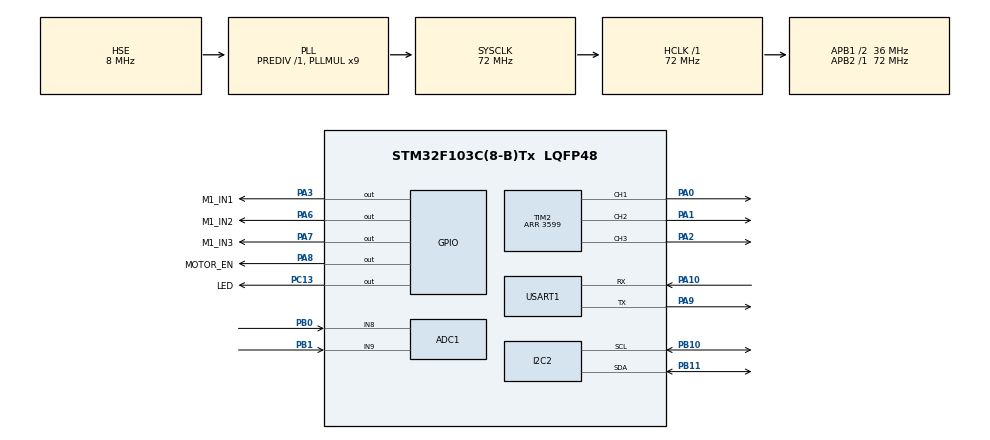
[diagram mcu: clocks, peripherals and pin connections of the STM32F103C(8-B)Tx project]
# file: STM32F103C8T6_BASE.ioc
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ADC1.Channel-0\#ChannelRegularConversion=ADC_CHANNEL_8
ADC1.Channel-1\#ChannelRegularConversion=ADC_CHANNEL_9
ADC1.NbrOfConversion=2
ADC1.NbrOfConversionFlag=1
ADC1.Rank-0\#ChannelRegularConversion=1
ADC1.Rank-1\#ChannelRegularConversion=2
ADC1.SamplingTime-0\#ChannelRegularConversion=ADC_SAMPLETIME_55CYCLES_5
ADC1.SamplingTime-1\#ChannelRegularConversion=ADC_SAMPLETIME_55CYCLES_5
ADC1.master=1
Mcu.Family=STM32F1
Mcu.Name=STM32F103C(8-B)Tx
Mcu.Package=LQFP48
NVIC.PriorityGroup=NVIC_PRIORITYGROUP_4
PA0-WKUP.Signal=S_TIM2_CH1_ETR
PA1.Signal=S_TIM2_CH2
PA10.Mode=Asynchronous
PA10.Signal=USART1_RX
PA13.Mode=Serial_Wire
PA13.Signal=SYS_JTMS-SWDIO
PA14.Mode=Serial_Wire
PA14.Signal=SYS_JTCK-SWCLK
PA2.Signal=S_TIM2_CH3
PA3.GPIO_Label=M1_IN1
PA3.Signal=GPIO_Output
PA6.GPIO_Label=M1_IN2
PA6.Signal=GPIO_Output
PA7.GPIO_Label=M1_IN3
PA7.Signal=GPIO_Output
PA8.GPIO_Label=MOTOR_EN
PA8.GPIO_PuPd=GPIO_NOPULL
PA8.Signal=GPIO_Output
PA9.Mode=Asynchronous
PA9.Signal=USART1_TX
PB0.Signal=ADCx_IN8
PB1.Signal=ADCx_IN9
PB10.Mode=I2C
PB10.Signal=I2C2_SCL
PB11.Mode=I2C
PB11.Signal=I2C2_SDA
PC13-TAMPER-RTC.GPIO_Label=LED
PC13-TAMPER-RTC.Signal=GPIO_Output
PC14-OSC32_IN.Mode=LSE-External-Oscillator
PC14-OSC32_IN.Signal=RCC_OSC32_IN
PC15-OSC32_OUT.Mode=LSE-External-Oscillator
PC15-OSC32_OUT.Signal=RCC_OSC32_OUT
PD0-OSC_IN.Mode=HSE-External-Oscillator
PD0-OSC_IN.Signal=RCC_OSC_IN
PD1-OSC_OUT.Mode=HSE-External-Oscillator
PD1-OSC_OUT.Signal=RCC_OSC_OUT
ProjectManager.HeapSize=0x200
ProjectManager.StackSize=0x400
ProjectManager.TargetToolchain=MDK-ARM V5.32
RCC.ADCPresc=RCC_ADCPCLK2_DIV6
RCC.AHBFreq_Value=72000000
RCC.APB1CLKDivider=RCC_HCLK_DIV2
RCC.APB1Freq_Value=36000000
RCC.APB1TimFreq_Value=72000000
RCC.APB2Freq_Value=72000000
RCC.APB2TimFreq_Value=72000000
RCC.HCLKFreq_Value=72000000
RCC.PLLMUL=RCC_PLL_MUL9
RCC.PLLSourceVirtual=RCC_PLLSOURCE_HSE
RCC.SYSCLKFreq_VALUE=72000000
RCC.SYSCLKSource=RCC_SYSCLKSOURCE_PLLCLK
RCC.USBFreq_Value=72000000
SH.ADCx_IN8.0=ADC1_IN8,IN8
SH.ADCx_IN9.0=ADC1_IN9,IN9
SH.S_TIM2_CH1_ETR.0=TIM2_CH1,PWM Generation1 CH1
SH.S_TIM2_CH2.0=TIM2_CH2,PWM Generation2 CH2
SH.S_TIM2_CH3.0=TIM2_CH3,PWM Generation3 CH3
TIM2.Channel-PWM\ Generation1\ CH1=TIM_CHANNEL_1
TIM2.Channel-PWM\ Generation2\ CH2=TIM_CHANNEL_2
TIM2.Channel-PWM\ Generation3\ CH3=TIM_CHANNEL_3
TIM2.Period=3599
USART1.VirtualMode=VM_ASYNC
VP_TIM2_VS_ClockSourceINT.Mode=Internal
board=custom

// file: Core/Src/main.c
/* USER CODE BEGIN Header */
/**
  ******************************************************************************
  * @file           : main.c
  * @brief          : Main program body
  ******************************************************************************
  * @attention
  *
  * Copyright (c) 2026 STMicroelectronics.
  * All rights reserved.
  *
  * This software is licensed under terms that can be found in the LICENSE file
  * in the root directory of this software component.
  * If no LICENSE file comes with this software, it is provided AS-IS.
  *
  ******************************************************************************
  */
/* USER CODE END Header */
#include "main.h"

/* USER CODE BEGIN Includes */
#include "app_baseline.h"

/* USER CODE END Includes */

ADC_HandleTypeDef hadc1;

I2C_HandleTypeDef hi2c2;

TIM_HandleTypeDef htim2;

UART_HandleTypeDef huart1;

void SystemClock_Config(void);
static void MX_GPIO_Init(void);
static void MX_ADC1_Init(void);
static void MX_I2C2_Init(void);
static void MX_TIM2_Init(void);
static void MX_USART1_UART_Init(void);

int main(void)
{

  /* MCU Configuration--------------------------------------------------------*/

  /* Reset of all peripherals, Initializes the Flash interface and the Systick. */
  HAL_Init();

  /* Configure the system clock */
  SystemClock_Config();

  /* Initialize all configured peripherals */
  MX_GPIO_Init();
  MX_ADC1_Init();
  MX_I2C2_Init();
  MX_TIM2_Init();
  MX_USART1_UART_Init();
  /* USER CODE BEGIN 2 */
  app_baseline_init();

  /* USER CODE END 2 */

  /* Infinite loop */
  while (1)
  {

    /* USER CODE BEGIN 3 */
    app_baseline_poll();
  }
  /* USER CODE END 3 */
}

void SystemClock_Config(void)
{
  RCC_OscInitTypeDef RCC_OscInitStruct = {0};
  RCC_ClkInitTypeDef RCC_ClkInitStruct = {0};
  RCC_PeriphCLKInitTypeDef PeriphClkInit = {0};

  /** Initializes the RCC Oscillators according to the specified parameters
  * in the RCC_OscInitTypeDef structure.
  */
  RCC_OscInitStruct.OscillatorType = RCC_OSCILLATORTYPE_HSE;
  RCC_OscInitStruct.HSEState = RCC_HSE_ON;
  RCC_OscInitStruct.HSEPredivValue = RCC_HSE_PREDIV_DIV1;
  RCC_OscInitStruct.HSIState = RCC_HSI_ON;
  RCC_OscInitStruct.PLL.PLLState = RCC_PLL_ON;
  RCC_OscInitStruct.PLL.PLLSource = RCC_PLLSOURCE_HSE;
  RCC_OscInitStruct.PLL.PLLMUL = RCC_PLL_MUL9;
  if (HAL_RCC_OscConfig(&RCC_OscInitStruct) != HAL_OK)
  {
    Error_Handler();
  }

  /** Initializes the CPU, AHB and APB buses clocks
  */
  RCC_ClkInitStruct.ClockType = RCC_CLOCKTYPE_HCLK|RCC_CLOCKTYPE_SYSCLK
                              |RCC_CLOCKTYPE_PCLK1|RCC_CLOCKTYPE_PCLK2;
  RCC_ClkInitStruct.SYSCLKSource = RCC_SYSCLKSOURCE_PLLCLK;
  RCC_ClkInitStruct.AHBCLKDivider = RCC_SYSCLK_DIV1;
  RCC_ClkInitStruct.APB1CLKDivider = RCC_HCLK_DIV2;
  RCC_ClkInitStruct.APB2CLKDivider = RCC_HCLK_DIV1;

  if (HAL_RCC_ClockConfig(&RCC_ClkInitStruct, FLASH_LATENCY_2) != HAL_OK)
  {
    Error_Handler();
  }
  PeriphClkInit.PeriphClockSelection = RCC_PERIPHCLK_ADC;
  PeriphClkInit.AdcClockSelection = RCC_ADCPCLK2_DIV6;
  if (HAL_RCCEx_PeriphCLKConfig(&PeriphClkInit) != HAL_OK)
  {
    Error_Handler();
  }
}

static void MX_ADC1_Init(void)
{

  ADC_ChannelConfTypeDef sConfig = {0};

  /** Common config
  */
  hadc1.Instance = ADC1;
  hadc1.Init.ScanConvMode = ADC_SCAN_ENABLE;
  hadc1.Init.ContinuousConvMode = DISABLE;
  hadc1.Init.DiscontinuousConvMode = DISABLE;
  hadc1.Init.ExternalTrigConv = ADC_SOFTWARE_START;
  hadc1.Init.DataAlign = ADC_DATAALIGN_RIGHT;
  hadc1.Init.NbrOfConversion = 2;
  if (HAL_ADC_Init(&hadc1) != HAL_OK)
  {
    Error_Handler();
  }

  /** Configure Regular Channel
  */
  sConfig.Channel = ADC_CHANNEL_8;
  sConfig.Rank = ADC_REGULAR_RANK_1;
  sConfig.SamplingTime = ADC_SAMPLETIME_55CYCLES_5;
  if (HAL_ADC_ConfigChannel(&hadc1, &sConfig) != HAL_OK)
  {
    Error_Handler();
  }

  /** Configure Regular Channel
  */
  sConfig.Channel = ADC_CHANNEL_9;
  sConfig.Rank = ADC_REGULAR_RANK_2;
  if (HAL_ADC_ConfigChannel(&hadc1, &sConfig) != HAL_OK)
  {
    Error_Handler();
  }

}

static void MX_I2C2_Init(void)
{

  hi2c2.Instance = I2C2;
  hi2c2.Init.ClockSpeed = 100000;
  hi2c2.Init.DutyCycle = I2C_DUTYCYCLE_2;
  hi2c2.Init.OwnAddress1 = 0;
  hi2c2.Init.AddressingMode = I2C_ADDRESSINGMODE_7BIT;
  hi2c2.Init.DualAddressMode = I2C_DUALADDRESS_DISABLE;
  hi2c2.Init.OwnAddress2 = 0;
  hi2c2.Init.GeneralCallMode = I2C_GENERALCALL_DISABLE;
  hi2c2.Init.NoStretchMode = I2C_NOSTRETCH_DISABLE;
  if (HAL_I2C_Init(&hi2c2) != HAL_OK)
  {
    Error_Handler();
  }

}

static void MX_TIM2_Init(void)
{

  TIM_ClockConfigTypeDef sClockSourceConfig = {0};
  TIM_MasterConfigTypeDef sMasterConfig = {0};
  TIM_OC_InitTypeDef sConfigOC = {0};

  htim2.Instance = TIM2;
  htim2.Init.Prescaler = 0;
  htim2.Init.CounterMode = TIM_COUNTERMODE_UP;
  htim2.Init.Period = 3599;
  htim2.Init.ClockDivision = TIM_CLOCKDIVISION_DIV1;
  htim2.Init.AutoReloadPreload = TIM_AUTORELOAD_PRELOAD_DISABLE;
  if (HAL_TIM_Base_Init(&htim2) != HAL_OK)
  {
    Error_Handler();
  }
  sClockSourceConfig.ClockSource = TIM_CLOCKSOURCE_INTERNAL;
  if (HAL_TIM_ConfigClockSource(&htim2, &sClockSourceConfig) != HAL_OK)
  {
    Error_Handler();
  }
  if (HAL_TIM_PWM_Init(&htim2) != HAL_OK)
  {
    Error_Handler();
  }
  sMasterConfig.MasterOutputTrigger = TIM_TRGO_RESET;
  sMasterConfig.MasterSlaveMode = TIM_MASTERSLAVEMODE_DISABLE;
  if (HAL_TIMEx_MasterConfigSynchronization(&htim2, &sMasterConfig) != HAL_OK)
  {
    Error_Handler();
  }
  sConfigOC.OCMode = TIM_OCMODE_PWM1;
  sConfigOC.Pulse = 0;
  sConfigOC.OCPolarity = TIM_OCPOLARITY_HIGH;
  sConfigOC.OCFastMode = TIM_OCFAST_DISABLE;
  if (HAL_TIM_PWM_ConfigChannel(&htim2, &sConfigOC, TIM_CHANNEL_1) != HAL_OK)
  {
    Error_Handler();
  }
  if (HAL_TIM_PWM_ConfigChannel(&htim2, &sConfigOC, TIM_CHANNEL_2) != HAL_OK)
  {
    Error_Handler();
  }
  if (HAL_TIM_PWM_ConfigChannel(&htim2, &sConfigOC, TIM_CHANNEL_3) != HAL_OK)
  {
    Error_Handler();
  }
  HAL_TIM_MspPostInit(&htim2);

}

static void MX_USART1_UART_Init(void)
{

  huart1.Instance = USART1;
  huart1.Init.BaudRate = 115200;
  huart1.Init.WordLength = UART_WORDLENGTH_8B;
  huart1.Init.StopBits = UART_STOPBITS_1;
  huart1.Init.Parity = UART_PARITY_NONE;
  huart1.Init.Mode = UART_MODE_TX_RX;
  huart1.Init.HwFlowCtl = UART_HWCONTROL_NONE;
  huart1.Init.OverSampling = UART_OVERSAMPLING_16;
  if (HAL_UART_Init(&huart1) != HAL_OK)
  {
    Error_Handler();
  }

}

static void MX_GPIO_Init(void)
{
  GPIO_InitTypeDef GPIO_InitStruct = {0};

  /* GPIO Ports Clock Enable */
  __HAL_RCC_GPIOC_CLK_ENABLE();
  __HAL_RCC_GPIOD_CLK_ENABLE();
  __HAL_RCC_GPIOA_CLK_ENABLE();
  __HAL_RCC_GPIOB_CLK_ENABLE();

  /*Configure GPIO pin Output Level */
  HAL_GPIO_WritePin(LED_GPIO_Port, LED_Pin, GPIO_PIN_RESET);

  /*Configure GPIO pin Output Level */
  HAL_GPIO_WritePin(GPIOA, M1_IN1_Pin|M1_IN2_Pin|M1_IN3_Pin|MOTOR_EN_Pin, GPIO_PIN_RESET);

  /*Configure GPIO pin : LED_Pin */
  GPIO_InitStruct.Pin = LED_Pin;
  GPIO_InitStruct.Mode = GPIO_MODE_OUTPUT_PP;
  GPIO_InitStruct.Pull = GPIO_NOPULL;
  GPIO_InitStruct.Speed = GPIO_SPEED_FREQ_LOW;
  HAL_GPIO_Init(LED_GPIO_Port, &GPIO_InitStruct);

  /*Configure GPIO pins : M1_IN1_Pin M1_IN2_Pin M1_IN3_Pin MOTOR_EN_Pin */
  GPIO_InitStruct.Pin = M1_IN1_Pin|M1_IN2_Pin|M1_IN3_Pin|MOTOR_EN_Pin;
  GPIO_InitStruct.Mode = GPIO_MODE_OUTPUT_PP;
  GPIO_InitStruct.Pull = GPIO_NOPULL;
  GPIO_InitStruct.Speed = GPIO_SPEED_FREQ_LOW;
  HAL_GPIO_Init(GPIOA, &GPIO_InitStruct);

}

void Error_Handler(void)
{
  __disable_irq();
  while (1)
  {
  }
}
